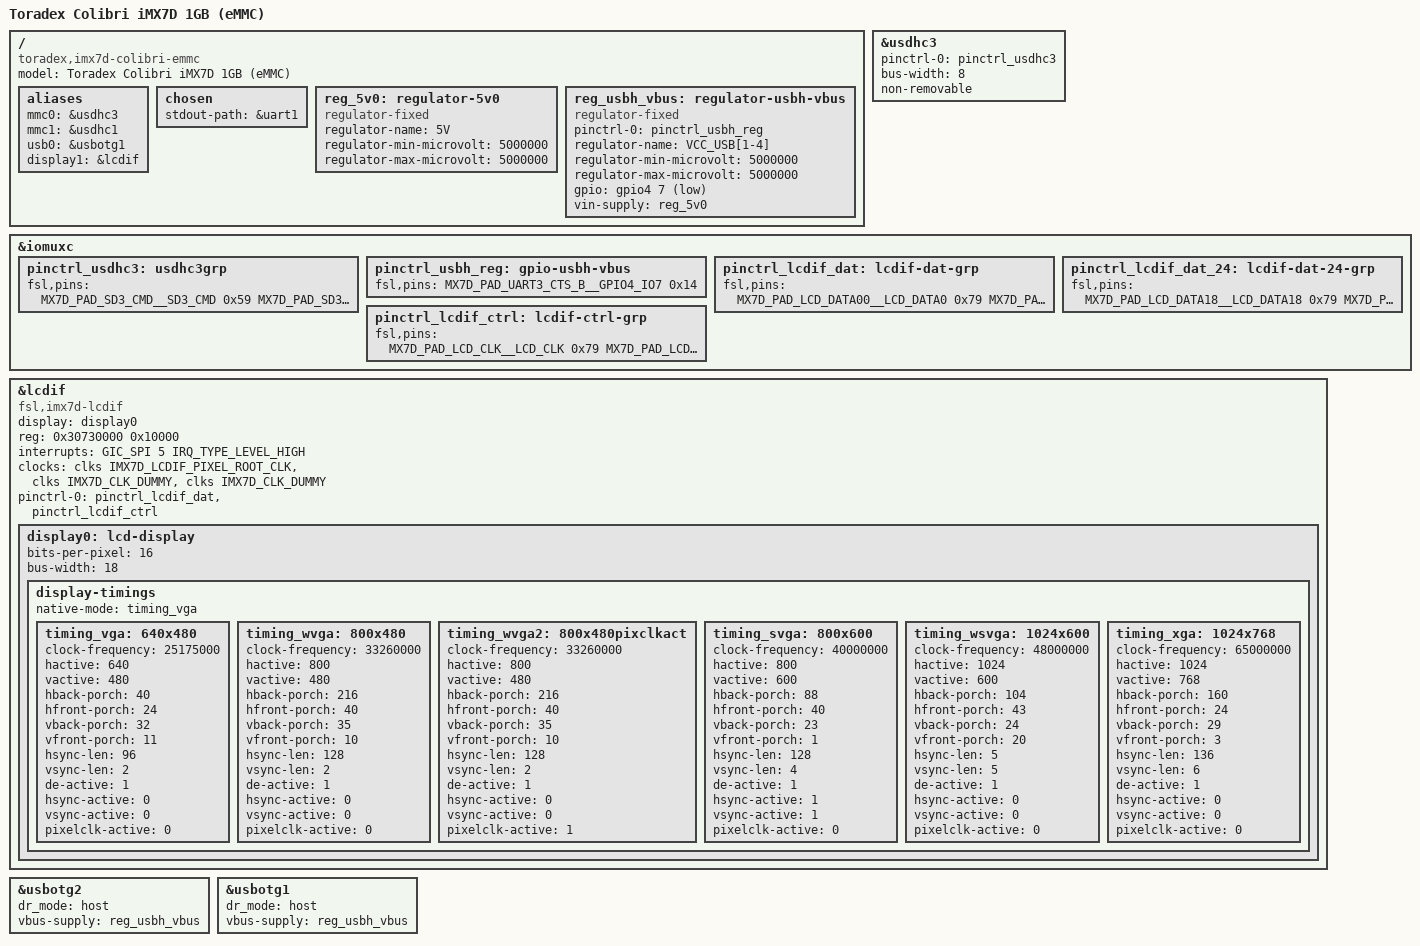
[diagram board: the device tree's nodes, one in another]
// SPDX-License-Identifier: GPL-2.0+ OR X11
/*
 * Copyright 2019 Toradex AG
 */

/dts-v1/;
#include "imx7-colibri.dtsi"

/ {
	model = "Toradex Colibri iMX7D 1GB (eMMC)";
	compatible = "toradex,imx7d-colibri-emmc", "fsl,imx7d";

	aliases {
		mmc0 = &usdhc3;
		mmc1 = &usdhc1;
		usb0 = &usbotg1; /* required for ums */
		display1 = &lcdif;
	};

	chosen {
		stdout-path = &uart1;
	};

	reg_5v0: regulator-5v0 {
		compatible = "regulator-fixed";
		regulator-name = "5V";
		regulator-min-microvolt = <5000000>;
		regulator-max-microvolt = <5000000>;
	};

	reg_usbh_vbus: regulator-usbh-vbus {
		compatible = "regulator-fixed";
		pinctrl-names = "default";
		pinctrl-0 = <&pinctrl_usbh_reg>;
		regulator-name = "VCC_USB[1-4]";
		regulator-min-microvolt = <5000000>;
		regulator-max-microvolt = <5000000>;
		gpio = <&gpio4 7 GPIO_ACTIVE_LOW>;
		vin-supply = <&reg_5v0>;
	};
};

&usdhc3 {
	pinctrl-names = "default";
	pinctrl-0 = <&pinctrl_usdhc3>;
	bus-width = <8>;
	non-removable;
	status = "okay";
};

&iomuxc {
	pinctrl_usdhc3: usdhc3grp {
		fsl,pins = <
			MX7D_PAD_SD3_CMD__SD3_CMD		0x59
			MX7D_PAD_SD3_CLK__SD3_CLK		0x19
			MX7D_PAD_SD3_DATA0__SD3_DATA0		0x59
			MX7D_PAD_SD3_DATA1__SD3_DATA1		0x59
			MX7D_PAD_SD3_DATA2__SD3_DATA2		0x59
			MX7D_PAD_SD3_DATA3__SD3_DATA3		0x59
			MX7D_PAD_SD3_DATA4__SD3_DATA4		0x59
			MX7D_PAD_SD3_DATA5__SD3_DATA5		0x59
			MX7D_PAD_SD3_DATA6__SD3_DATA6		0x59
			MX7D_PAD_SD3_DATA7__SD3_DATA7		0x59
			MX7D_PAD_SD3_STROBE__SD3_STROBE         0x19
		>;
	};

	pinctrl_usbh_reg: gpio-usbh-vbus {
		fsl,pins = <
			MX7D_PAD_UART3_CTS_B__GPIO4_IO7	0x14
		>;
	};

	pinctrl_lcdif_dat: lcdif-dat-grp {
		fsl,pins = <
			MX7D_PAD_LCD_DATA00__LCD_DATA0		0x79
			MX7D_PAD_LCD_DATA01__LCD_DATA1		0x79
			MX7D_PAD_LCD_DATA02__LCD_DATA2		0x79
			MX7D_PAD_LCD_DATA03__LCD_DATA3		0x79
			MX7D_PAD_LCD_DATA04__LCD_DATA4		0x79
			MX7D_PAD_LCD_DATA05__LCD_DATA5		0x79
			MX7D_PAD_LCD_DATA06__LCD_DATA6		0x79
			MX7D_PAD_LCD_DATA07__LCD_DATA7		0x79
			MX7D_PAD_LCD_DATA08__LCD_DATA8		0x79
			MX7D_PAD_LCD_DATA09__LCD_DATA9		0x79
			MX7D_PAD_LCD_DATA10__LCD_DATA10		0x79
			MX7D_PAD_LCD_DATA11__LCD_DATA11		0x79
			MX7D_PAD_LCD_DATA12__LCD_DATA12		0x79
			MX7D_PAD_LCD_DATA13__LCD_DATA13		0x79
			MX7D_PAD_LCD_DATA14__LCD_DATA14		0x79
			MX7D_PAD_LCD_DATA15__LCD_DATA15		0x79
			MX7D_PAD_LCD_DATA16__LCD_DATA16		0x79
			MX7D_PAD_LCD_DATA17__LCD_DATA17		0x79
		>;
	};

	pinctrl_lcdif_dat_24: lcdif-dat-24-grp {
		fsl,pins = <
			MX7D_PAD_LCD_DATA18__LCD_DATA18		0x79
			MX7D_PAD_LCD_DATA19__LCD_DATA19		0x79
			MX7D_PAD_LCD_DATA20__LCD_DATA20		0x79
			MX7D_PAD_LCD_DATA21__LCD_DATA21		0x79
			MX7D_PAD_LCD_DATA22__LCD_DATA22		0x79
			MX7D_PAD_LCD_DATA23__LCD_DATA23		0x79
		>;
	};

	pinctrl_lcdif_ctrl: lcdif-ctrl-grp {
		fsl,pins = <
			MX7D_PAD_LCD_CLK__LCD_CLK		0x79
			MX7D_PAD_LCD_ENABLE__LCD_ENABLE		0x79
			MX7D_PAD_LCD_VSYNC__LCD_VSYNC		0x79
			MX7D_PAD_LCD_HSYNC__LCD_HSYNC		0x79
		>;
	};
};

&lcdif {
	display = <&display0>;
	status = "okay";

	compatible = "fsl,imx7d-lcdif", "fsl,imx28-lcdif";
	reg = <0x30730000 0x10000>;
	interrupts = <GIC_SPI 5 IRQ_TYPE_LEVEL_HIGH>;
	clocks = <&clks IMX7D_LCDIF_PIXEL_ROOT_CLK>,
	       <&clks IMX7D_CLK_DUMMY>,
	       <&clks IMX7D_CLK_DUMMY>;
	clock-names = "pix", "axi", "disp_axi";

	pinctrl-names = "default";
	pinctrl-0 = <&pinctrl_lcdif_dat
		     &pinctrl_lcdif_ctrl>;

	display0: lcd-display {
		bits-per-pixel = <16>;
		bus-width = <18>;

		display-timings {
			native-mode = <&timing_vga>;

			/* Standard VGA timing */
			timing_vga: 640x480 {
				clock-frequency = <25175000>;
				hactive = <640>;
				vactive = <480>;
				hback-porch = <40>;
				hfront-porch = <24>;
				vback-porch = <32>;
				vfront-porch = <11>;
				hsync-len = <96>;
				vsync-len = <2>;

				de-active = <1>;
				hsync-active = <0>;
				vsync-active = <0>;
				pixelclk-active = <0>;
			};

			/* WVGA Timing, e.g. EDT ET070080DH6 */
			timing_wvga: 800x480 {
				clock-frequency = <33260000>;
				hactive = <800>;
				vactive = <480>;
				hback-porch = <216>;
				hfront-porch = <40>;
				vback-porch = <35>;
				vfront-porch = <10>;
				hsync-len = <128>;
				vsync-len = <2>;

				de-active = <1>;
				hsync-active = <0>;
				vsync-active = <0>;
				pixelclk-active = <0>;
			};
			/* WVGA Timing, TouchRevolution Fusion 7" */
			timing_wvga2: 800x480pixclkact {
				clock-frequency = <33260000>;
				hactive = <800>;
				vactive = <480>;
				hback-porch = <216>;
				hfront-porch = <40>;
				vback-porch = <35>;
				vfront-porch = <10>;
				hsync-len = <128>;
				vsync-len = <2>;

				de-active = <1>;
				hsync-active = <0>;
				vsync-active = <0>;
				pixelclk-active = <1>;
			};
			/* Standard SVGA timing */
			timing_svga: 800x600 {
				clock-frequency = <40000000>;
				hactive = <800>;
				vactive = <600>;
				hback-porch = <88>;
				hfront-porch = <40>;
				vback-porch = <23>;
				vfront-porch = <1>;
				hsync-len = <128>;
				vsync-len = <4>;

				de-active = <1>;
				hsync-active = <1>;
				vsync-active = <1>;
				pixelclk-active = <0>;
			};
			/* TouchRevolution Fusion 10"/CLAA101NC05 10.1 inch */
			timing_wsvga: 1024x600 {
				clock-frequency = <48000000>;
				hactive = <1024>;
				vactive = <600>;
				hback-porch = <104>;
				hfront-porch = <43>;
				vback-porch = <24>;
				vfront-porch = <20>;
				hsync-len = <5>;
				vsync-len = <5>;

				de-active = <1>;
				hsync-active = <0>;
				vsync-active = <0>;
				pixelclk-active = <0>;
			};
			/* Standard XGA timing */
			timing_xga: 1024x768 {
				clock-frequency = <65000000>;
				hactive = <1024>;
				vactive = <768>;
				hback-porch = <160>;
				hfront-porch = <24>;
				vback-porch = <29>;
				vfront-porch = <3>;
				hsync-len = <136>;
				vsync-len = <6>;

				de-active = <1>;
				hsync-active = <0>;
				vsync-active = <0>;
				pixelclk-active = <0>;
			};
		};
	};
};
&usbotg2 {
	dr_mode = "host";
	vbus-supply = <&reg_usbh_vbus>;
	status = "okay";
};

&usbotg1 {
	dr_mode = "host";
	vbus-supply = <&reg_usbh_vbus>;
	status = "okay";
};
